# nrf9120_mlm1_modem register map
Vendor: Nordic Semiconductor; Series: nrf91; File version: 1
CPU: CM4 r0p1, little endian, MPU, no FPU, 3 interrupt priority bits
Registers are 32-bit, read-write, reset 0x0 unless marked. A register's access mark holds for its fields unless they carry their own. Offsets are from the block's base; [hi:lo] are bit positions; {n}, {i} and the like mark numbered series.

## LWDT — Watchdog Timer 0
Base 0x40027000
Same registers: SWDT 0x40028000
0x00 TASKS_START wo — Start the watchdog
  [0] TASKS_START
    1=Trigger task
0x04 TASKS_STOP wo — Stop the watchdog timer. Only available in timer mode.
  [0] TASKS_STOP
    1=Trigger task
0x100 EVENTS_TIMEOUT — Watchdog timeout
  [0] EVENTS_TIMEOUT
    0=NotGenerated (Event not generated); 1=Generated (Event generated)
0x304 INTENSET — Enable interrupt
  [0] TIMEOUT — Write '1' to enable interrupt for event TIMEOUT
    on read: 0=Disabled (Read: Disabled); 1=Enabled (Read: Enabled) | on write: 1=Set (Enable)
0x308 INTENCLR — Disable interrupt
  [0] TIMEOUT — Write '1' to disable interrupt for event TIMEOUT
    on read: 0=Disabled (Read: Disabled); 1=Enabled (Read: Enabled) | on write: 1=Clear (Disable)
0x400 RUNSTATUS ro
  [0] RUNSTATUS — Indicates whether or not the watchdog is running
    0=NotRunning (Watchdog not running); 1=Running (Watchdog is running)
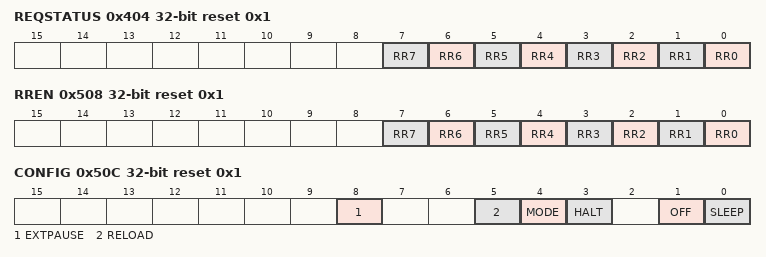
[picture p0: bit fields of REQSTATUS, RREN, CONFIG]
0x404 REQSTATUS ro reset 0x1 — Request status
  [n] RR{n} (n=0..7) — Request status for RR[{n}] register
    0=DisabledOrRequested (RR[{n}] register is not enabled, or are already requesting reload); 1=EnabledAndUnrequested (RR[{n}] register is enabled, and are not yet requesting reload)
0x408 RCNT — Reload count
  [1:0] RCNT — Reload count, number of times the watchdog has been reloaded (kicked)
0x504 CRV reset 0xFFFFFFFF — Counter reload value
  [31:0] CRV — Counter reload value in number of cycles of the 32.768 kHz clock
0x508 RREN reset 0x1 — Enable register for reload request registers
  [n] RR{n} (n=0..7) — Enable or disable RR[{n}] register
    0=Disabled (Disable RR[{n}] register); 1=Enabled (Enable RR[{n}] register)
0x50C CONFIG reset 0x1 — Configuration register
  [8] EXTPAUSE — Configure the watchdog to either be paused, or kept running, while the EXTPAUSE signal is set
    0=Pause watchdog while the EXTPAUSE signal is set; 1=Run (Keep the watchdog running while EXTPAUSE signal is set)
  [5] RELOAD — Enable or disable possibility to reload the watchdog counter between TIMEOUT and watchdog reset
    0=Disabled; 1=Enabled
  [4] MODE — Watchdog operation mode
    0=Watchdog (Use the watchdog timer as a watchdog); 1=Timer (Use the watchdog timer as a timer)
  [3] HALT — Configure the watchdog to either be paused, or kept running, while the CPU is halted by the debugger
    0=Pause watchdog while the CPU is halted by the debugger; 1=Run (Keep the watchdog running while the CPU is halted by the debugger)
  [1] OFF — Enable or disable override of system OFF mode
    0=Disabled (No impact on system OFF mode); 1=Enabled (Prevent system OFF mode when watchdog is running)
  [0] SLEEP — Configure the watchdog to either be paused, or kept running, while the CPU is sleeping
    0=Pause watchdog while the CPU is sleeping; 1=Run (Keep the watchdog running while the CPU is sleeping)
{0x600+4i} RR[{i}] (i=0..7) wo — Description collection: Reload request n
  [31:0] RR — Reload request register
    0x6E524635=Reload (Value to request a reload of the watchdog timer)
0xFFC POWER reset 0x1 — Peripheral power control
  [0] POWER — Peripheral power control. The peripheral and its registers will be reset to its initial state by switching the peripheral off and then back on again.
    0=Disabled (Peripheral is powered off); 1=Enabled (Peripheral is powered on)

## RNG — Random Number Generator
Base 0x40029000
0x00 TASKS_START wo — Task starting the random number generator
  [0] TASKS_START
    1=Trigger task
0x04 TASKS_STOP wo — Task stopping the random number generator
  [0] TASKS_STOP
    1=Trigger task
0x100 EVENTS_VALRDY — Event being generated for every new random number written to the VALUE register
  [0] EVENTS_VALRDY
    0=NotGenerated (Event not generated); 1=Generated (Event generated)
0x200 SHORTS — Shortcuts between local events and tasks
  [0] VALRDY_STOP — Shortcut between event VALRDY and task STOP
    0=Disabled (Disable shortcut); 1=Enabled (Enable shortcut)
0x300 INTEN — Enable or disable interrupt
  [0] VALRDY — Enable or disable interrupt for event VALRDY
    0=Disabled; 1=Enabled
0x304 INTENSET — Enable interrupt
  [0] VALRDY — Write '1' to enable interrupt for event VALRDY
    on read: 0=Disabled (Read: Disabled); 1=Enabled (Read: Enabled) | on write: 1=Set (Enable)
0x308 INTENCLR — Disable interrupt
  [0] VALRDY — Write '1' to disable interrupt for event VALRDY
    on read: 0=Disabled (Read: Disabled); 1=Enabled (Read: Enabled) | on write: 1=Clear (Disable)
0x504 CONFIG — Configuration register
  [0] DERCEN — Bias correction
    0=Disabled; 1=Enabled
0x508 VALUE ro — Output random number
  [7:0] VALUE — Generated random number
0xFFC POWER reset 0x1 — Peripheral power control
  [0] POWER — Peripheral power control. The peripheral and its registers will be reset to its initial state by switching the peripheral off and then back on again.
    0=Disabled (Peripheral is powered off); 1=Enabled (Peripheral is powered on)
